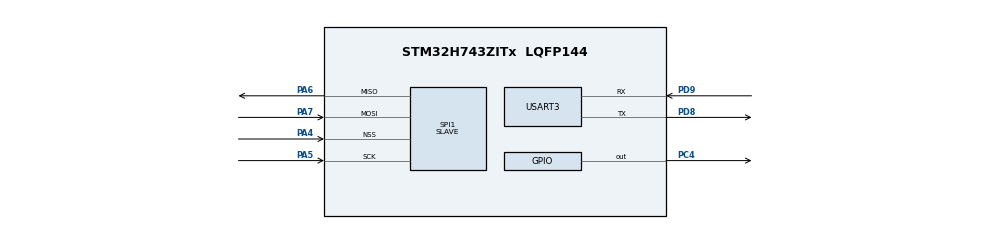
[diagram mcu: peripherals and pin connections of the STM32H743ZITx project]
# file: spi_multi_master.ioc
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Mcu.Family=STM32H7
Mcu.Name=STM32H743ZITx
Mcu.Package=LQFP144
NVIC.PriorityGroup=NVIC_PRIORITYGROUP_4
PA4.Mode=NSS_Signal_Hard_Input
PA4.Signal=SPI1_NSS
PA5.Mode=Full_Duplex_Slave
PA5.Signal=SPI1_SCK
PA6.Mode=Full_Duplex_Slave
PA6.Signal=SPI1_MISO
PA7.Mode=Full_Duplex_Slave
PA7.Signal=SPI1_MOSI
PC4.Signal=GPIO_Output
PD8.Mode=Asynchronous
PD8.Signal=USART3_TX
PD9.Mode=Asynchronous
PD9.Signal=USART3_RX
ProjectManager.HeapSize=0x200
ProjectManager.StackSize=0x400
ProjectManager.TargetToolchain=SW4STM32
RCC.ADCFreq_Value=129000000
RCC.APB1Freq_Value=64000000
RCC.APB2Freq_Value=64000000
RCC.APB3Freq_Value=64000000
RCC.APB4Freq_Value=64000000
RCC.CortexFreq_Value=64000000
RCC.HCLKFreq_Value=64000000
RCC.SYSCLKFreq_VALUE=64000000
RCC.USBFreq_Value=129000000
SPI1.Direction=SPI_DIRECTION_2LINES
SPI1.Mode=SPI_MODE_SLAVE
SPI1.VirtualNSS=VM_NSSHARD
SPI1.VirtualType=VM_SLAVE
USART3.VirtualMode-Asynchronous=VM_ASYNC
board=custom

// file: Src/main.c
/**
  ******************************************************************************
  * @file           : main.c
  * @brief          : Main program body
  ******************************************************************************
  ** This notice applies to any and all portions of this file
  * that are not between comment pairs USER CODE BEGIN and
  * USER CODE END. Other portions of this file, whether
  * inserted by the user or by software development tools
  * are owned by their respective copyright owners.
  *
  * COPYRIGHT(c) 2018 STMicroelectronics
  *
  * Redistribution and use in source and binary forms, with or without modification,
  * are permitted provided that the following conditions are met:
  *   1. Redistributions of source code must retain the above copyright notice,
  *      this list of conditions and the following disclaimer.
  *   2. Redistributions in binary form must reproduce the above copyright notice,
  *      this list of conditions and the following disclaimer in the documentation
  *      and/or other materials provided with the distribution.
  *   3. Neither the name of STMicroelectronics nor the names of its contributors
  *      may be used to endorse or promote products derived from this software
  *      without specific prior written permission.
  *
  * THIS SOFTWARE IS PROVIDED BY THE COPYRIGHT HOLDERS AND CONTRIBUTORS "AS IS"
  * AND ANY EXPRESS OR IMPLIED WARRANTIES, INCLUDING, BUT NOT LIMITED TO, THE
  * IMPLIED WARRANTIES OF MERCHANTABILITY AND FITNESS FOR A PARTICULAR PURPOSE ARE
  * DISCLAIMED. IN NO EVENT SHALL THE COPYRIGHT HOLDER OR CONTRIBUTORS BE LIABLE
  * FOR ANY DIRECT, INDIRECT, INCIDENTAL, SPECIAL, EXEMPLARY, OR CONSEQUENTIAL
  * DAMAGES (INCLUDING, BUT NOT LIMITED TO, PROCUREMENT OF SUBSTITUTE GOODS OR
  * SERVICES; LOSS OF USE, DATA, OR PROFITS; OR BUSINESS INTERRUPTION) HOWEVER
  * CAUSED AND ON ANY THEORY OF LIABILITY, WHETHER IN CONTRACT, STRICT LIABILITY,
  * OR TORT (INCLUDING NEGLIGENCE OR OTHERWISE) ARISING IN ANY WAY OUT OF THE USE
  * OF THIS SOFTWARE, EVEN IF ADVISED OF THE POSSIBILITY OF SUCH DAMAGE.
  *
  ******************************************************************************
  */
#include "main.h"
#include "stm32h7xx_hal.h"

SPI_HandleTypeDef hspi1;

UART_HandleTypeDef huart3;

/* USER CODE BEGIN PV */
/* Private variables ---------------------------------------------------------*/

/* USER CODE END PV */

void SystemClock_Config(void);
static void MX_GPIO_Init(void);
static void MX_SPI1_Init(void);
static void MX_USART3_UART_Init(void);

/* USER CODE BEGIN PFP */
/* Private function prototypes -----------------------------------------------*/
HAL_StatusTypeDef spi_take_control_of_bus (SPI_HandleTypeDef *hspi);
/* USER CODE END PFP */

int main(void)
{

  /* MCU Configuration----------------------------------------------------------*/

  /* Reset of all peripherals, Initializes the Flash interface and the Systick. */
  HAL_Init();

  /* Configure the system clock */
  SystemClock_Config();

  /* Initialize all configured peripherals */
  MX_GPIO_Init();
  MX_SPI1_Init();
  MX_USART3_UART_Init();
  /* USER CODE BEGIN 2 */

  uint8_t *msg = "Trillium!";
  /* USER CODE END 2 */

  /* Infinite loop */
  while (1)
  {

  /* USER CODE BEGIN 3 */
	  HAL_UART_Transmit(&huart3, msg, 9, 50);
	  HAL_Delay(1000);
  }
  /* USER CODE END 3 */

}

void SystemClock_Config(void)
{

  RCC_OscInitTypeDef RCC_OscInitStruct;
  RCC_ClkInitTypeDef RCC_ClkInitStruct;
  RCC_PeriphCLKInitTypeDef PeriphClkInitStruct;

    /**Supply configuration update enable
    */
  MODIFY_REG(PWR->CR3, PWR_CR3_SCUEN, 0);

    /**Configure the main internal regulator output voltage
    */
  __HAL_PWR_VOLTAGESCALING_CONFIG(PWR_REGULATOR_VOLTAGE_SCALE3);

  while ((PWR->D3CR & (PWR_D3CR_VOSRDY)) != PWR_D3CR_VOSRDY)
  {

  }
    /**Initializes the CPU, AHB and APB busses clocks
    */
  RCC_OscInitStruct.OscillatorType = RCC_OSCILLATORTYPE_HSI;
  RCC_OscInitStruct.HSIState = RCC_HSI_DIV1;
  RCC_OscInitStruct.HSICalibrationValue = 16;
  RCC_OscInitStruct.PLL.PLLState = RCC_PLL_ON;
  RCC_OscInitStruct.PLL.PLLSource = RCC_PLLSOURCE_HSI;
  RCC_OscInitStruct.PLL.PLLM = 32;
  RCC_OscInitStruct.PLL.PLLN = 129;
  RCC_OscInitStruct.PLL.PLLP = 2;
  RCC_OscInitStruct.PLL.PLLQ = 2;
  RCC_OscInitStruct.PLL.PLLR = 2;
  RCC_OscInitStruct.PLL.PLLRGE = RCC_PLL1VCIRANGE_1;
  RCC_OscInitStruct.PLL.PLLVCOSEL = RCC_PLL1VCOWIDE;
  RCC_OscInitStruct.PLL.PLLFRACN = 0;
  if (HAL_RCC_OscConfig(&RCC_OscInitStruct) != HAL_OK)
  {
    _Error_Handler(__FILE__, __LINE__);
  }

    /**Initializes the CPU, AHB and APB busses clocks
    */
  RCC_ClkInitStruct.ClockType = RCC_CLOCKTYPE_HCLK|RCC_CLOCKTYPE_SYSCLK
                              |RCC_CLOCKTYPE_PCLK1|RCC_CLOCKTYPE_PCLK2
                              |RCC_CLOCKTYPE_D3PCLK1|RCC_CLOCKTYPE_D1PCLK1;
  RCC_ClkInitStruct.SYSCLKSource = RCC_SYSCLKSOURCE_HSI;
  RCC_ClkInitStruct.SYSCLKDivider = RCC_SYSCLK_DIV1;
  RCC_ClkInitStruct.AHBCLKDivider = RCC_HCLK_DIV1;
  RCC_ClkInitStruct.APB3CLKDivider = RCC_APB3_DIV1;
  RCC_ClkInitStruct.APB1CLKDivider = RCC_APB1_DIV1;
  RCC_ClkInitStruct.APB2CLKDivider = RCC_APB2_DIV1;
  RCC_ClkInitStruct.APB4CLKDivider = RCC_APB4_DIV1;

  if (HAL_RCC_ClockConfig(&RCC_ClkInitStruct, FLASH_LATENCY_0) != HAL_OK)
  {
    _Error_Handler(__FILE__, __LINE__);
  }

  PeriphClkInitStruct.PeriphClockSelection = RCC_PERIPHCLK_USART3|RCC_PERIPHCLK_SPI1;
  PeriphClkInitStruct.Spi123ClockSelection = RCC_SPI123CLKSOURCE_PLL;
  PeriphClkInitStruct.Usart234578ClockSelection = RCC_USART234578CLKSOURCE_D2PCLK1;
  if (HAL_RCCEx_PeriphCLKConfig(&PeriphClkInitStruct) != HAL_OK)
  {
    _Error_Handler(__FILE__, __LINE__);
  }

    /**Configure the Systick interrupt time
    */
  HAL_SYSTICK_Config(SystemCoreClock/1000);

    /**Configure the Systick
    */
  HAL_SYSTICK_CLKSourceConfig(SYSTICK_CLKSOURCE_HCLK);

  /* SysTick_IRQn interrupt configuration */
  HAL_NVIC_SetPriority(SysTick_IRQn, 0, 0);
}

/* SPI1 init function */
static void MX_SPI1_Init(void)
{

  /* SPI1 parameter configuration*/
  hspi1.Instance = SPI1;
  hspi1.Init.Mode = SPI_MODE_SLAVE;
  hspi1.Init.Direction = SPI_DIRECTION_2LINES;
  hspi1.Init.DataSize = SPI_DATASIZE_4BIT;
  hspi1.Init.CLKPolarity = SPI_POLARITY_LOW;
  hspi1.Init.CLKPhase = SPI_PHASE_1EDGE;
  hspi1.Init.NSS = SPI_NSS_HARD_INPUT;
  hspi1.Init.FirstBit = SPI_FIRSTBIT_MSB;
  hspi1.Init.TIMode = SPI_TIMODE_DISABLE;
  hspi1.Init.CRCCalculation = SPI_CRCCALCULATION_DISABLE;
  hspi1.Init.CRCPolynomial = 7;
  hspi1.Init.NSSPMode = SPI_NSS_PULSE_DISABLE;
  hspi1.Init.NSSPolarity = SPI_NSS_POLARITY_LOW;
  hspi1.Init.FifoThreshold = SPI_FIFO_THRESHOLD_01DATA;
  hspi1.Init.TxCRCInitializationPattern = SPI_CRC_INITIALIZATION_ALL_ZERO_PATTERN;
  hspi1.Init.RxCRCInitializationPattern = SPI_CRC_INITIALIZATION_ALL_ZERO_PATTERN;
  hspi1.Init.MasterSSIdleness = SPI_MASTER_SS_IDLENESS_00CYCLE;
  hspi1.Init.MasterInterDataIdleness = SPI_MASTER_INTERDATA_IDLENESS_00CYCLE;
  hspi1.Init.MasterReceiverAutoSusp = SPI_MASTER_RX_AUTOSUSP_DISABLE;
  hspi1.Init.MasterKeepIOState = SPI_MASTER_KEEP_IO_STATE_DISABLE;
  hspi1.Init.IOSwap = SPI_IO_SWAP_DISABLE;
  if (HAL_SPI_Init(&hspi1) != HAL_OK)
  {
    _Error_Handler(__FILE__, __LINE__);
  }

}

/* USART3 init function */
static void MX_USART3_UART_Init(void)
{

  huart3.Instance = USART3;
  huart3.Init.BaudRate = 115200;
  huart3.Init.WordLength = UART_WORDLENGTH_8B;
  huart3.Init.StopBits = UART_STOPBITS_1;
  huart3.Init.Parity = UART_PARITY_NONE;
  huart3.Init.Mode = UART_MODE_TX_RX;
  huart3.Init.HwFlowCtl = UART_HWCONTROL_NONE;
  huart3.Init.OverSampling = UART_OVERSAMPLING_16;
  huart3.Init.OneBitSampling = UART_ONE_BIT_SAMPLE_DISABLE;
  huart3.Init.Prescaler = UART_PRESCALER_DIV1;
  huart3.Init.FIFOMode = UART_FIFOMODE_DISABLE;
  huart3.Init.TXFIFOThreshold = UART_TXFIFO_THRESHOLD_1_8;
  huart3.Init.RXFIFOThreshold = UART_RXFIFO_THRESHOLD_1_8;
  huart3.AdvancedInit.AdvFeatureInit = UART_ADVFEATURE_NO_INIT;
  if (HAL_UART_Init(&huart3) != HAL_OK)
  {
    _Error_Handler(__FILE__, __LINE__);
  }

}

/** Configure pins as
        * Analog
        * Input
        * Output
        * EVENT_OUT
        * EXTI
*/
static void MX_GPIO_Init(void)
{

  GPIO_InitTypeDef GPIO_InitStruct;

  /* GPIO Ports Clock Enable */
  __HAL_RCC_GPIOA_CLK_ENABLE();
  __HAL_RCC_GPIOC_CLK_ENABLE();
  __HAL_RCC_GPIOD_CLK_ENABLE();

  /*Configure GPIO pin Output Level */
  HAL_GPIO_WritePin(GPIOC, GPIO_PIN_4, GPIO_PIN_RESET);

  /*Configure GPIO pin : PC4 */
  GPIO_InitStruct.Pin = GPIO_PIN_4;
  GPIO_InitStruct.Mode = GPIO_MODE_OUTPUT_PP;
  GPIO_InitStruct.Pull = GPIO_NOPULL;
  GPIO_InitStruct.Speed = GPIO_SPEED_FREQ_LOW;
  HAL_GPIO_Init(GPIOC, &GPIO_InitStruct);

}

/* USER CODE BEGIN 4 */
HAL_StatusTypeDef spi_take_control_of_bus (SPI_HandleTypeDef *hspi) {

}
/* USER CODE END 4 */

void _Error_Handler(char *file, int line)
{
  while(1)
  {
  }
}

/************************ (C) COPYRIGHT STMicroelectronics *****END OF FILE****/
